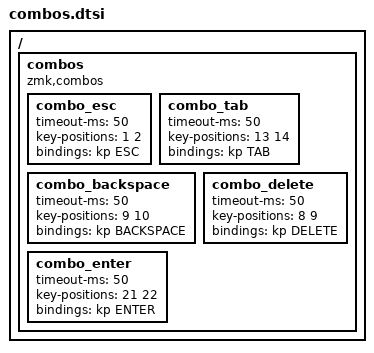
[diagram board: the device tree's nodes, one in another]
/ {
  combos {
    compatible = "zmk,combos";
    combo_esc {
      timeout-ms = <50>;
      key-positions = <1 2>;
      bindings = <&kp ESC>;
    };
    combo_tab {
      timeout-ms = <50>;
      key-positions = <13 14>;
      bindings = <&kp TAB>;
    };
    combo_backspace {
      timeout-ms = <50>;
      key-positions = <9 10>;
      bindings = <&kp BACKSPACE>;
    };
    combo_delete {
      timeout-ms = <50>;
      key-positions = <8 9>;
      bindings = <&kp DELETE>;
    };
    combo_enter {
      timeout-ms = <50>;
      key-positions = <21 22>;
      bindings = <&kp ENTER>;
    };
  };
};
